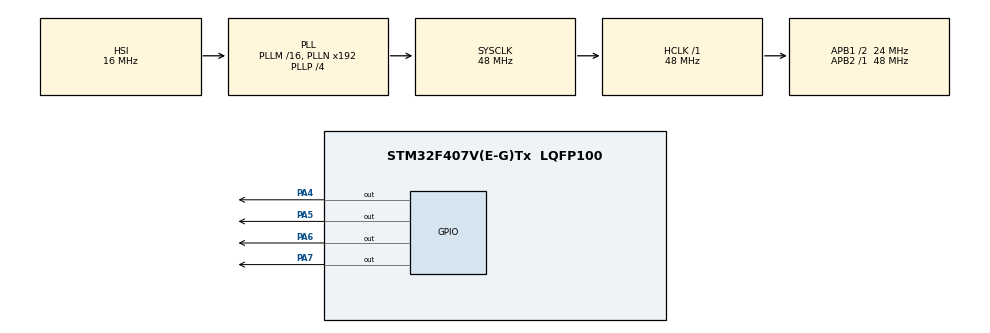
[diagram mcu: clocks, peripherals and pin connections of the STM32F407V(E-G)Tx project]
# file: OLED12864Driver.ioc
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Mcu.Family=STM32F4
RCC.CortexFreq_Value=48000000
RCC.APB1CLKDivider=RCC_HCLK_DIV2
RCC.SYSCLKSource=RCC_SYSCLKSOURCE_PLLCLK
ProjectManager.StackSize=0x400
PA13.Signal=SYS_JTMS-SWDIO
ProjectManager.TargetToolchain=STM32CubeIDE
RCC.HCLKFreq_Value=48000000
RCC.APB2TimFreq_Value=48000000
RCC.LSE_VALUE=32768
RCC.AHBFreq_Value=48000000
PA5.Signal=GPIO_Output
RCC.HSE_VALUE=25000000
board=custom
RCC.VCOOutputFreq_Value=192000000
PA4.GPIO_Speed=GPIO_SPEED_FREQ_MEDIUM
PA7.GPIO_Speed=GPIO_SPEED_FREQ_MEDIUM
RCC.APB2Freq_Value=48000000
PA14.Mode=Serial_Wire
PA13.Mode=Serial_Wire
Mcu.Name=STM32F407V(E-G)Tx
PA4.Signal=GPIO_Output
RCC.SYSCLKFreq_VALUE=48000000
Mcu.Package=LQFP100
PA6.Signal=GPIO_Output
PA14.Signal=SYS_JTCK-SWCLK
ProjectManager.HeapSize=0x200
RCC.HSI_VALUE=16000000
RCC.PLLP=RCC_PLLP_DIV4
PA5.GPIO_Speed=GPIO_SPEED_FREQ_MEDIUM
NVIC.PriorityGroup=NVIC_PRIORITYGROUP_4
RCC.APB1TimFreq_Value=48000000
PA6.GPIO_Speed=GPIO_SPEED_FREQ_MEDIUM
RCC.APB1Freq_Value=24000000
PA7.Signal=GPIO_Output

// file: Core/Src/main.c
/* USER CODE BEGIN Header */
/**
  ******************************************************************************
  * @file           : main.c
  * @brief          : Main program body
  ******************************************************************************
  * @attention
  *
  * <h2><center>&copy; Copyright (c) 2020 STMicroelectronics.
  * All rights reserved.</center></h2>
  *
  * This software component is licensed by ST under BSD 3-Clause license,
  * the "License"; You may not use this file except in compliance with the
  * License. You may obtain a copy of the License at:
  *                        opensource.org/licenses/BSD-3-Clause
  *
  ******************************************************************************
  */
/* USER CODE END Header */
#include "main.h"

void SystemClock_Config(void);
static void MX_GPIO_Init(void);

int main(void)
{

  /* MCU Configuration--------------------------------------------------------*/

  /* Reset of all peripherals, Initializes the Flash interface and the Systick. */
  HAL_Init();

  /* Configure the system clock */
  SystemClock_Config();

  /* Initialize all configured peripherals */
  MX_GPIO_Init();
  /* USER CODE BEGIN 2 */
  OLED_Init();
  OLED_Point point;
  point.x = 13;
  point.y = 15;
  /* USER CODE END 2 */

  /* Infinite loop */
  while (1)
  {

  }
}

void SystemClock_Config(void)
{
  RCC_OscInitTypeDef RCC_OscInitStruct = {0};
  RCC_ClkInitTypeDef RCC_ClkInitStruct = {0};

  /** Configure the main internal regulator output voltage
  */
  __HAL_RCC_PWR_CLK_ENABLE();
  __HAL_PWR_VOLTAGESCALING_CONFIG(PWR_REGULATOR_VOLTAGE_SCALE1);
  /** Initializes the RCC Oscillators according to the specified parameters
  * in the RCC_OscInitTypeDef structure.
  */
  RCC_OscInitStruct.OscillatorType = RCC_OSCILLATORTYPE_HSI;
  RCC_OscInitStruct.HSIState = RCC_HSI_ON;
  RCC_OscInitStruct.HSICalibrationValue = RCC_HSICALIBRATION_DEFAULT;
  RCC_OscInitStruct.PLL.PLLState = RCC_PLL_ON;
  RCC_OscInitStruct.PLL.PLLSource = RCC_PLLSOURCE_HSI;
  RCC_OscInitStruct.PLL.PLLM = 16;
  RCC_OscInitStruct.PLL.PLLN = 192;
  RCC_OscInitStruct.PLL.PLLP = RCC_PLLP_DIV4;
  RCC_OscInitStruct.PLL.PLLQ = 4;
  if (HAL_RCC_OscConfig(&RCC_OscInitStruct) != HAL_OK)
  {
    Error_Handler();
  }
  /** Initializes the CPU, AHB and APB buses clocks
  */
  RCC_ClkInitStruct.ClockType = RCC_CLOCKTYPE_HCLK | RCC_CLOCKTYPE_SYSCLK | RCC_CLOCKTYPE_PCLK1 | RCC_CLOCKTYPE_PCLK2;
  RCC_ClkInitStruct.SYSCLKSource = RCC_SYSCLKSOURCE_PLLCLK;
  RCC_ClkInitStruct.AHBCLKDivider = RCC_SYSCLK_DIV1;
  RCC_ClkInitStruct.APB1CLKDivider = RCC_HCLK_DIV2;
  RCC_ClkInitStruct.APB2CLKDivider = RCC_HCLK_DIV1;

  if (HAL_RCC_ClockConfig(&RCC_ClkInitStruct, FLASH_LATENCY_1) != HAL_OK)
  {
    Error_Handler();
  }
}

static void MX_GPIO_Init(void)
{
  GPIO_InitTypeDef GPIO_InitStruct = {0};

  /* GPIO Ports Clock Enable */
  __HAL_RCC_GPIOA_CLK_ENABLE();

  /*Configure GPIO pin Output Level */
  HAL_GPIO_WritePin(GPIOA, GPIO_PIN_4 | GPIO_PIN_5 | GPIO_PIN_6 | GPIO_PIN_7, GPIO_PIN_RESET);

  /*Configure GPIO pins : PA4 PA5 PA6 PA7 */
  GPIO_InitStruct.Pin = GPIO_PIN_4 | GPIO_PIN_5 | GPIO_PIN_6 | GPIO_PIN_7;
  GPIO_InitStruct.Mode = GPIO_MODE_OUTPUT_PP;
  GPIO_InitStruct.Pull = GPIO_NOPULL;
  GPIO_InitStruct.Speed = GPIO_SPEED_FREQ_MEDIUM;
  HAL_GPIO_Init(GPIOA, &GPIO_InitStruct);
}

void Error_Handler(void)
{
}

/************************ (C) COPYRIGHT STMicroelectronics *****END OF FILE****/
